# Special_Function_19 register map
Vendor: Texas Instruments
Peripheral module from a debugger description file (folder msp430).
Registers are 8-bit, read-write, reset 0x0 unless marked. A register's access mark holds for its fields unless they carry their own. Offsets are as the file gives them; lines under a group give offsets from that group; [hi:lo] are bit positions; {n}, {i} and the like mark numbered series; 'fields as' and 'values as' point back to an identical list; <NAME> marks a mode.

## Special_Function
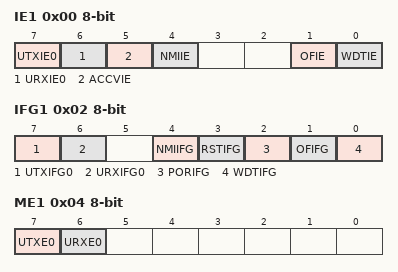
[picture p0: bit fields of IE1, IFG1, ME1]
0x00 IE1 — Interrupt Enable 1
  [7] UTXIE0
  [6] URXIE0
  [5] ACCVIE — Flash Access Violation Interrupt Enable
  [4] NMIIE — NMI Interrupt Enable
  [1] OFIE — Osc. Fault Interrupt Enable
  [0] WDTIE — Watchdog Interrupt Enable
0x02 IFG1 — Interrupt Flag 1
  [7] UTXIFG0
  [6] URXIFG0
  [4] NMIIFG — NMI Interrupt Flag
  [3] RSTIFG — Reset Interrupt Flag
  [2] PORIFG — Power On Interrupt Flag
  [1] OFIFG — Osc. Fault Interrupt Flag
  [0] WDTIFG — Watchdog Interrupt Flag
0x04 ME1 — Module Enable 1
  [7] UTXE0, [6] URXE0
